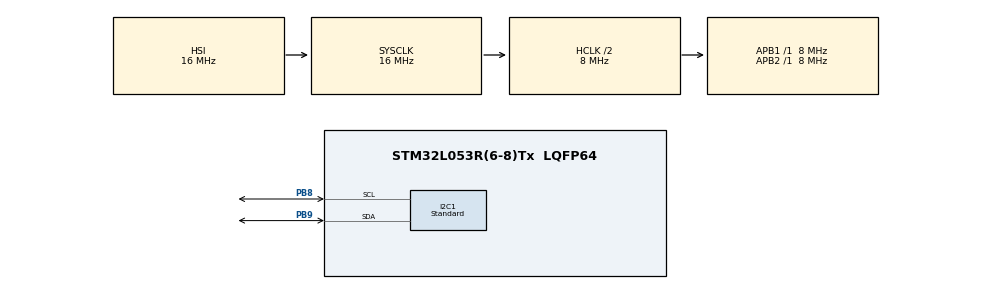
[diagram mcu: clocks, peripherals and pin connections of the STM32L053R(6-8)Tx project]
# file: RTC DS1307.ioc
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I2C1.I2C_Speed_Mode=I2C_Standard
I2C1.Timing=0x00201D2B
Mcu.Family=STM32L0
Mcu.Name=STM32L053R(6-8)Tx
Mcu.Package=LQFP64
PB8.GPIO_Pu=GPIO_NOPULL
PB8.GPIO_Speed=GPIO_SPEED_FREQ_HIGH
PB8.Mode=I2C
PB8.Signal=I2C1_SCL
PB9.GPIO_Pu=GPIO_NOPULL
PB9.GPIO_Speed=GPIO_SPEED_FREQ_HIGH
PB9.Mode=I2C
PB9.Signal=I2C1_SDA
ProjectManager.HeapSize=0x200
ProjectManager.StackSize=0x400
ProjectManager.TargetToolchain=STM32CubeIDE
RCC.AHBCLKDivider=RCC_SYSCLK_DIV2
RCC.AHBFreq_Value=8000000
RCC.APB1Freq_Value=8000000
RCC.APB1TimFreq_Value=8000000
RCC.APB2Freq_Value=8000000
RCC.APB2TimFreq_Value=8000000
RCC.HCLKFreq_Value=8000000
RCC.HSE_VALUE=8000000
RCC.HSI16_VALUE=16000000
RCC.HSI48_VALUE=48000000
RCC.HSI_VALUE=16000000
RCC.LSE_VALUE=32768
RCC.MSI_VALUE=2097000
RCC.SYSCLKFreq_VALUE=16000000
RCC.SYSCLKSource=RCC_SYSCLKSOURCE_HSI
RCC.VCOOutputFreq_Value=48000000
board=NUCLEO-L053R8

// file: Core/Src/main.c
/* USER CODE BEGIN Header */
/**
  ******************************************************************************
  * @file           : main.c
  * @brief          : Main program body
  ******************************************************************************
  * @attention
  *
  * Copyright (c) 2025 STMicroelectronics.
  * All rights reserved.
  *
  * This software is licensed under terms that can be found in the LICENSE file
  * in the root directory of this software component.
  * If no LICENSE file comes with this software, it is provided AS-IS.
  *
  ******************************************************************************
  */
/* USER CODE END Header */
#include "main.h"

/* USER CODE BEGIN Includes */
#include "DS1307.h"
/* USER CODE END Includes */

I2C_HandleTypeDef hi2c1;

/* USER CODE BEGIN PV */

BIT data;
RTC_DS1307 clock;
/* USER CODE END PV */

void SystemClock_Config(void);
static void MX_GPIO_Init(void);
static void MX_I2C1_Init(void);

int main(void)
{

  /* MCU Configuration--------------------------------------------------------*/

  /* Reset of all peripherals, Initializes the Flash interface and the Systick. */
  HAL_Init();

  /* Configure the system clock */
  SystemClock_Config();

  /* Initialize all configured peripherals */
  MX_GPIO_Init();
  MX_I2C1_Init();
  /* USER CODE BEGIN 2 */

  DS1307_STARTUP(&hi2c1);
  DS1307_GET_TIME(&clock);

  /* USER CODE END 2 */

  /* Infinite loop */
  while (1)
  {

  }
}

void SystemClock_Config(void)
{
  RCC_OscInitTypeDef RCC_OscInitStruct = {0};
  RCC_ClkInitTypeDef RCC_ClkInitStruct = {0};
  RCC_PeriphCLKInitTypeDef PeriphClkInit = {0};

  /** Configure the main internal regulator output voltage
  */
  __HAL_PWR_VOLTAGESCALING_CONFIG(PWR_REGULATOR_VOLTAGE_SCALE1);

  /** Initializes the RCC Oscillators according to the specified parameters
  * in the RCC_OscInitTypeDef structure.
  */
  RCC_OscInitStruct.OscillatorType = RCC_OSCILLATORTYPE_HSI;
  RCC_OscInitStruct.HSIState = RCC_HSI_ON;
  RCC_OscInitStruct.HSICalibrationValue = RCC_HSICALIBRATION_DEFAULT;
  RCC_OscInitStruct.PLL.PLLState = RCC_PLL_NONE;
  if (HAL_RCC_OscConfig(&RCC_OscInitStruct) != HAL_OK)
  {
    Error_Handler();
  }

  /** Initializes the CPU, AHB and APB buses clocks
  */
  RCC_ClkInitStruct.ClockType = RCC_CLOCKTYPE_HCLK|RCC_CLOCKTYPE_SYSCLK
                              |RCC_CLOCKTYPE_PCLK1|RCC_CLOCKTYPE_PCLK2;
  RCC_ClkInitStruct.SYSCLKSource = RCC_SYSCLKSOURCE_HSI;
  RCC_ClkInitStruct.AHBCLKDivider = RCC_SYSCLK_DIV2;
  RCC_ClkInitStruct.APB1CLKDivider = RCC_HCLK_DIV1;
  RCC_ClkInitStruct.APB2CLKDivider = RCC_HCLK_DIV1;

  if (HAL_RCC_ClockConfig(&RCC_ClkInitStruct, FLASH_LATENCY_0) != HAL_OK)
  {
    Error_Handler();
  }
  PeriphClkInit.PeriphClockSelection = RCC_PERIPHCLK_I2C1;
  PeriphClkInit.I2c1ClockSelection = RCC_I2C1CLKSOURCE_PCLK1;
  if (HAL_RCCEx_PeriphCLKConfig(&PeriphClkInit) != HAL_OK)
  {
    Error_Handler();
  }
}

static void MX_I2C1_Init(void)
{

  hi2c1.Instance = I2C1;
  hi2c1.Init.Timing = 0x10420F13;
  hi2c1.Init.OwnAddress1 = 0;
  hi2c1.Init.AddressingMode = I2C_ADDRESSINGMODE_7BIT;
  hi2c1.Init.DualAddressMode = I2C_DUALADDRESS_DISABLE;
  hi2c1.Init.OwnAddress2 = 0;
  hi2c1.Init.OwnAddress2Masks = I2C_OA2_NOMASK;
  hi2c1.Init.GeneralCallMode = I2C_GENERALCALL_DISABLE;
  hi2c1.Init.NoStretchMode = I2C_NOSTRETCH_DISABLE;
  if (HAL_I2C_Init(&hi2c1) != HAL_OK)
  {
    Error_Handler();
  }

  /** Configure Analogue filter
  */
  if (HAL_I2CEx_ConfigAnalogFilter(&hi2c1, I2C_ANALOGFILTER_ENABLE) != HAL_OK)
  {
    Error_Handler();
  }

  /** Configure Digital filter
  */
  if (HAL_I2CEx_ConfigDigitalFilter(&hi2c1, 0) != HAL_OK)
  {
    Error_Handler();
  }

}

static void MX_GPIO_Init(void)
{
  /* USER CODE BEGIN MX_GPIO_Init_1 */
	GPIO_InitTypeDef GPIO_InitStruct = {0};

	__HAL_RCC_GPIOB_CLK_ENABLE();

	// Configura PB6 (SCL) e PB7 (SDA) para I2C1
	GPIO_InitStruct.Pin = GPIO_PIN_6 | GPIO_PIN_7;
	GPIO_InitStruct.Mode = GPIO_MODE_AF_OD;        // Alternate Function Open Drain
	GPIO_InitStruct.Pull = GPIO_PULLUP;            // Pull-up habilitado
	GPIO_InitStruct.Speed = GPIO_SPEED_FREQ_HIGH;
	GPIO_InitStruct.Alternate = GPIO_AF1_I2C1;     // AF1 para I2C1
	HAL_GPIO_Init(GPIOB, &GPIO_InitStruct);
  /* USER CODE END MX_GPIO_Init_1 */

  /* GPIO Ports Clock Enable */
  __HAL_RCC_GPIOB_CLK_ENABLE();

}

void Error_Handler(void)
{
  __disable_irq();
  while (1)
  {
  }
}
